# R7FA0E209 register map
Vendor: Renesas Electronics Corporation; Series: RA0; File version: 1.10.00
CPU: CM23 r1p0, little endian, no MPU, no FPU, VTOR, 2 interrupt priority bits, 64 interrupts
Registers are 16-bit, read-write, reset 0x0 unless marked. A register's access mark holds for its fields unless they carry their own. Offsets are from the block's base; [hi:lo] are bit positions; {n}, {i} and the like mark numbered series; 'fields as' and 'values as' point back to an identical list.

## SAU0 — Serial Array Unit 0
Base 0x400A2000
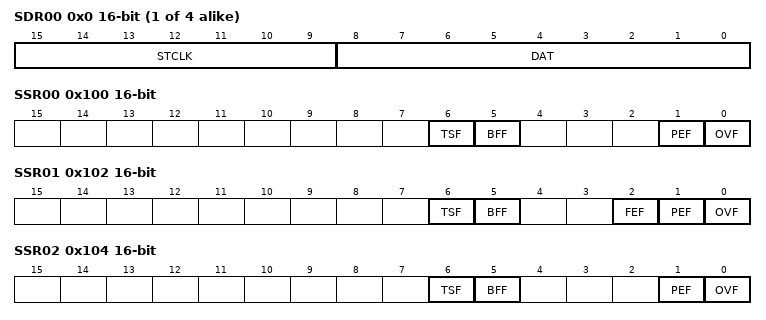
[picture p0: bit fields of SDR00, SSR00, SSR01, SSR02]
{0x0+2i} SDR0{i} (i=0..3) — Serial Data Register 0{i}
  [15:9] STCLK — Transfer Clock Setting by Dividing the Operation Clock
  [8:0] DAT — Data Buffer for Transmit and Receive
0x100 SSR00 ro — Serial Status Register 00
  [6] TSF — Flag Indicating the State of Communications for Channel n
    0=Communication is stopped or suspended; 1=Communication is in progress
  [5] BFF — Flag Indicating the State of the Buffer Register for Channel n
    0=Valid data is not stored in the SDRmn register; 1=Valid data is stored in the SDRmn register
  [1] PEF — Parity or ACK Error Detection Flag of Channel n
    0=No error occurs; 1=Parity error occurs (during UART reception), or ACK is not detected (during I2C transmission)
  [0] OVF — Overrun Error Detection Flag of Channel n
    0=No error occurs; 1=An error occurs
0x102 SSR01 ro — Serial Status Register 01
  [6] TSF — Flag Indicating the State of Communications for Channel n
    values as SSR00.TSF
  [5] BFF — Flag Indicating the State of the Buffer Register for Channel n
    values as SSR00.BFF
  [2] FEF — Framing Error Detection Flag of Channel n
    0=No error occurs; 1=An error occurs (during UART reception)
  [1] PEF — Parity or ACK Error Detection Flag of Channel n
    values as SSR00.PEF
  [0] OVF — Overrun Error Detection Flag of Channel n
    0=No error occurs; 1=An error occurs
0x104 SSR02 ro — Serial Status Register 02
  fields as SSR00
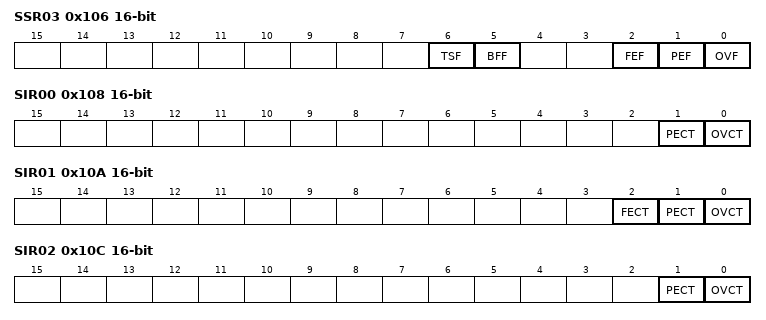
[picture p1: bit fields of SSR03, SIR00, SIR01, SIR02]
0x106 SSR03 ro — Serial Status Register 03
  fields as SSR01
0x108 SIR00 — Serial Flag Clear Trigger Register 00
  [1] PECT — Clear Trigger of Parity Error Flag of Channel n
    0=Not cleared; 1=Clears the PEF bit of the SSRmn register to 0
  [0] OVCT — Clear Trigger of Overrun Error Flag of Channel n
    0=Not cleared; 1=Clears the OVF bit of the SSRmn register to 0
0x10A SIR01 — Serial Flag Clear Trigger Register 01
  [2] FECT — Clear Trigger of Framing Error Flag of Channel n
    0=Not cleared; 1=Clears the FEF bit of the SSRmn register to 0
  [1] PECT — Clear Trigger of Parity Error Flag of Channel n
    values as SIR00.PECT
  [0] OVCT — Clear Trigger of Overrun Error Flag of Channel n
    values as SIR00.OVCT
0x10C SIR02 — Serial Flag Clear Trigger Register 02
  fields as SIR00
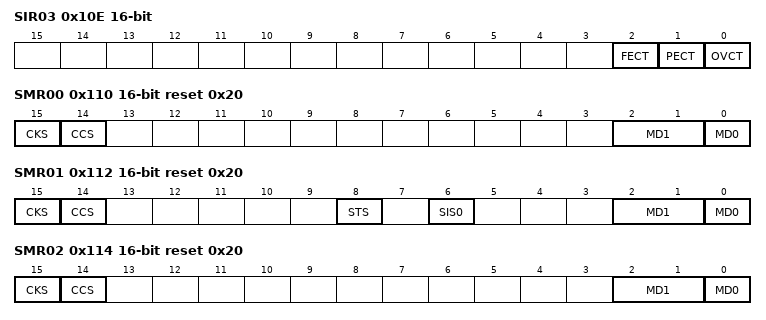
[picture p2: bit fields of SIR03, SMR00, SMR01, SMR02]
0x10E SIR03 — Serial Flag Clear Trigger Register 03
  fields as SIR01
0x110 SMR00 reset 0x20 — Serial Mode Register 00
  [15] CKS — Selection of Operation Clock (fMCK) of Channel n
    0=Operation clock CKm0 set by the SPSm register; 1=Operation clock CKm1 set by the SPSm register
  [14] CCS — Selection of Transfer Clock (fTCLK) of Channel n
    0=Divided operation clock fMCK specified by the CKS bit; 1=Clock input fSCK from the SCKp pin (slave transfer in simplified SPI mode)
  [2:1] MD1 — Setting of Channel n Operation Mode
    0=Simplified SPI mode; 1=UART mode; 2=Simplified I2C mode; 3=Setting prohibited
  [0] MD0 — Selection of Channel n Interrupt Source
    0=Transfer end interrupt; 1=Buffer empty interrupt (Occurs when data is transferred from the SDRmn register to the shift register.)
0x112 SMR01 reset 0x20 — Serial Mode Register 01
  [15] CKS — Selection of Operation Clock (fMCK) of Channel n
    values as SMR00.CKS
  [14] CCS — Selection of Transfer Clock (fTCLK) of Channel n
    values as SMR00.CCS
  [8] STS — Selection of Start Trigger Source
    0=Only software trigger is valid (selected for simplified SPI, UART transmission, and simplified I2C); 1=Valid edge of the RXDq pin (selected for UART reception)
  [6] SIS0 — Controls Inversion of Level of Channel n Receive Data in UART Mode
    0=Falling edge is detected as the start bit. The input communication data is captured as is.; 1=Rising edge is detected as the start bit. The input communication data is inverted and captured.
  [2:1] MD1 — Setting of Channel n Operation Mode
    values as SMR00.MD1
  [0] MD0 — Selection of Channel n Interrupt Source
    values as SMR00.MD0
0x114 SMR02 reset 0x20 — Serial Mode Register 02
  fields as SMR00
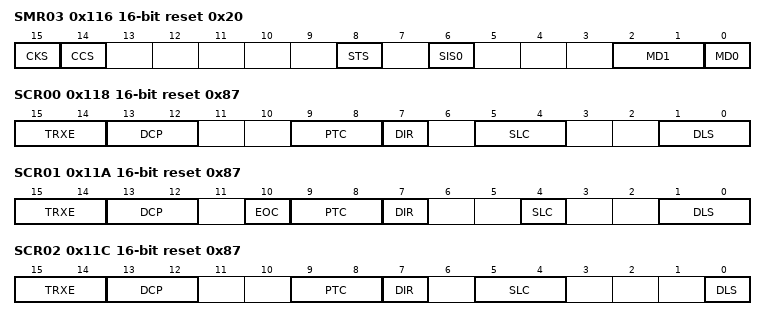
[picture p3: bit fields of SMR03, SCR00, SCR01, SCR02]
0x116 SMR03 reset 0x20 — Serial Mode Register 03
  fields as SMR01
0x118 SCR00 reset 0x87 — Serial Communication Operation Setting Register 00
  [15:14] TRXE — Setting of Channel 0 Operation Mode
    0=Disable communication; 1=Reception only; 2=Transmission only; 3=Transmission and reception
  [13:12] DCP — Selection of Data and Clock Phase in Simplified SPI Mode
    0=Type1 (SCK: inverted, Input timing: rising edge); 1=Type2 (SCK: non-inverted, Input timing: falling edge); 2=Type3 (SCK: inverted, Input timing: falling edge); 3=Type4 (SCK: non-inverted, Input timing: rising edge)
  [9:8] PTC — Setting of Parity Bit in UART Mode
    0=Transmission: Does not output the parity bit Reception: Receives without parity; 1=Transmission: Outputs 0 parity Reception: No parity determination; 2=Transmission: Outputs even parity Reception: Determines as even parity; 3=Transmission: Outputs odd parity Reception: Determines as odd parity
  [7] DIR — Selection of Data Transfer Sequence in Simplified SPI and UART Modes
    0=Inputs or outputs data with MSB first; 1=Inputs or outputs data with LSB first
  [5:4] SLC — Setting of Stop Bit in UART Mode
    0=No stop bit; 1=Stop bit length = 1 bit; 2=Stop bit length = 2 bits; 3=Setting prohibited
  [1:0] DLS — Setting of Data Length in Simplified SPI and UART Modes
    0=Setting prohibited; 1=9-bit data length (stored in bits 0 to 8 of the SDRm0 register) (settable in UART mode only); 2=7-bit data length (stored in bits 0 to 6 of the SDRm0 register); 3=8-bit data length (stored in bits 0 to 7 of the SDRm0 register)
0x11A SCR01 reset 0x87 — Serial Communication Operation Setting Register 01
  [15:14] TRXE — Setting of Channel 1 Operation Mode
    values as SCR00.TRXE
  [13:12] DCP — Selection of Data and Clock Phase in Simplified SPI Mode
    values as SCR00.DCP
  [10] EOC — Mask Control of Error Interrupt Signal SAU0_UART_ERRI0 (m = 0), SAU1_UART_ERRI2 (m = 1)
    0=Disables generation of error interrupt SAU0_UART_ERRI0 (m = 0), SAU1_UART_ERRI2 (m = 1) (SAUm_UART_RXIq is generated); 1=Enables generation of error interrupt SAU0_UART_ERRI0 (m = 0), SAU1_UART_ERRI2 (m = 1) (SAUm_UART_RXIq is not generated if an error occurs)
  [9:8] PTC — Setting of Parity Bit in UART Mode
    0=Transmission: Does not output the parity bit Reception: Receives without parity; 1=Transmission: Outputs 0 parity Reception: No parity judgment; 2=Transmission: Outputs even parity Reception: Determines as even parity; 3=Transmission: Outputs odd parity Reception: Determines as odd parity
  [7] DIR — Selection of Data Transfer Sequence in Simplified SPI and UART Modes
    values as SCR00.DIR
  [4] SLC — Setting of Stop Bit in UART Mode
    0=No stop bit; 1=Stop bit length = 1 bit
  [1:0] DLS — Setting of Data Length in Simplified SPI and UART Modes
    0=Setting prohibited; 1=9-bit data length (stored in the DAT[8:0] bits of the SDRm1 register) (settable in UART mode only); 2=7-bit data length (stored in the DAT[6:0] bits of the SDRm1 register); 3=8-bit data length (stored in the DAT[7:0] bits of the SDRm1 register)
0x11C SCR02 reset 0x87 — Serial Communication Operation Setting Register 02
  [15:14] TRXE — Setting of Channel 2 Operation Mode
    0=Disables communication; 1=Reception only; 2=Transmission only; 3=Transmission and reception
  [13:12] DCP — Selection of Data and Clock Phase in Simplified SPI Mode
    values as SCR00.DCP
  [9:8] PTC — Setting of Parity Bit in UART Mode
    values as SCR01.PTC
  [7] DIR — Selection of Data Transfer Sequence in Simplified SPI and UART Modes
    values as SCR00.DIR
  [5:4] SLC — Setting of Stop Bit in UART Mode
    values as SCR00.SLC
  [0] DLS — Setting of Data Length in Simplified SPI and UART Modes
    0=7-bit data length (stored in the DAT[6:0] bits of the SDR02 register); 1=8-bit data length (stored in the DAT[7:0] bits of the SDR02 register)
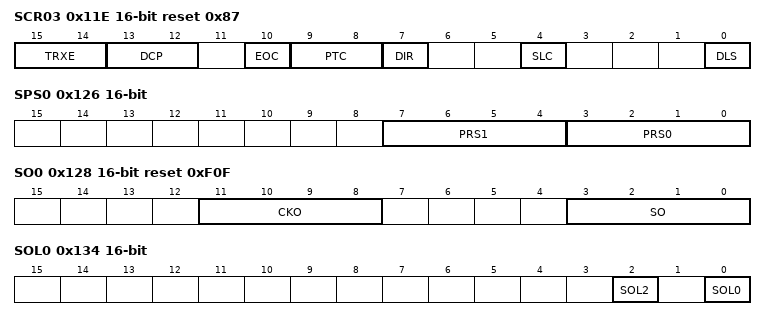
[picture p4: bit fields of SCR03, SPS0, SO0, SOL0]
0x11E SCR03 reset 0x87 — Serial Communication Operation Setting Register 03
  [15:14] TRXE — Setting of Operation Mode of Channel 3
    values as SCR00.TRXE
  [13:12] DCP — Selection of Data and Clock Phase in Simplified SPI Mode
    values as SCR00.DCP
  [10] EOC — Mask Control of Error Interrupt Signal SAU0_UART_ERRI1
    0=Disables generation of error interrupt SAU0_UART_ERRI1 (SAU0_UART_RXI1 is generated); 1=Enables generation of error interrupt SAU0_UART_ERRI1 (SAU0_UART_RXI1 is not generated if an error occurs)
  [9:8] PTC — Setting of Parity Bit in UART Mode
    values as SCR00.PTC
  [7] DIR — Selection of Data Transfer Sequence in Simplified SPI and UART Modes
    values as SCR00.DIR
  [4] SLC — Setting of Stop Bit in UART Mode
    0=No stop bit; 1=Stop bit length = 1 bit
  [0] DLS — Setting of Data Length in Simplified SPI and UART Modes
    0=7-bit data length (stored in the DAT[6:0] bits of the SDR03 register); 1=8-bit data length (stored in the DAT[7:0] bits of the SDR03 register)
0x120 SE0 ro — Serial Channel Enable Status Register 0
  [3:0] SE — Indication of whether Operation of Channel n is Enabled or Stopped.
    0=Operation stops; 1=Operation is enabled
0x122 SS0 — Serial Channel Start Register 0
  [3:0] SS — Operation Start Trigger of Channel n
    0=No trigger operation; 1=Set the SE0.SE[n] bit to 1 to place the channel in communications waiting state
0x124 ST0 — Serial Channel Stop Register 0
  [3:0] ST — Operation Stop Trigger of Channel n
    0=No trigger operation; 1=Clears the SE0.SE[n] bit to 0 and stops the communication operation
0x126 SPS0 — Serial Clock Select Register 0
  [7:4] PRS1 — Selection of Operation Clock (CKm1)
    0=PCLKB; 1=PCLKB/2; {v}=PCLKB/2^{v} (v=2..15)
  [3:0] PRS0 — Selection of Operation Clock (CKm0)
    0=PCLKB; 1=PCLKB/2; {v}=PCLKB/2^{v} (v=2..15)
0x128 SO0 reset 0xF0F — Serial Output Register 0
  [11:8] CKO — Serial Clock Output of Channel n
    0=Serial clock output value is 0; 1=Serial clock output value is 1
  [3:0] SO — Serial Data Output of Channel n
    0=Serial data output value is 0; 1=Serial data output value is 1
0x12A SOE0 — Serial Output Enable Register 0
  [3:0] SOE — Serial Output Enable or Stop of Channel n
    0=Stops output by serial communication operation; 1=Enables output by serial communication operation
0x134 SOL0 — Serial Output Level Register 0
  [2] SOL2 — Selects Inversion of the Level of the Transmit Data of Channel 2 in UART Mode
    0=Communication data is output as is; 1=Communication data is inverted and output
  [0] SOL0 — Selects Inversion of the Level of the Transmit Data of Channel 0 in UART Mode
    values as SOL2
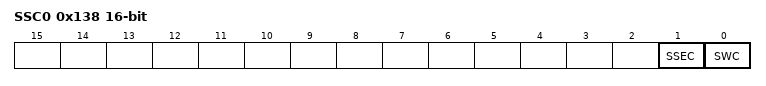
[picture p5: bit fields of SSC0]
0x138 SSC0 — Serial Standby Control Register 0
  [1] SSEC — Selection of whether to Enable or Disable the Generation of Communication Error Interrupts in the Snooze Mode
    0=Enable the generation of error interrupts SAU0_UART_ERRI0; 1=Disable the generation of error interrupts SAU0_UART_ERRI0
  [0] SWC — Setting of the Snooze Mode
    0=Do not use the Snooze mode function; 1=Use the Snooze mode function

## Notices in the file
This software is supplied by Renesas Electronics Corporation and is only intended for
use with Renesas products. No other uses are authorized. This software is owned by
Renesas Electronics Corporation and is protected under all applicable laws, including
copyright laws.
THIS SOFTWARE IS PROVIDED "AS IS" AND RENESAS MAKES NO WARRANTIES REGARDING
THIS SOFTWARE, WHETHER EXPRESS, IMPLIED OR STATUTORY, INCLUDING BUT NOT LIMITED TO
WARRANTIES OF MERCHANTABILITY, FITNESS FOR A PARTICULAR PURPOSE AND NON-INFRINGEMENT.
ALL SUCH WARRANTIES ARE EXPRESSLY DISCLAIMED. TO THE MAXIMUM EXTENT PERMITTED NOT
PROHIBITED BY LAW, NEITHER RENESAS ELECTRONICS CORPORATION NOR ANY OF ITS AFFILIATED
COMPANIES SHALL BE LIABLE FOR ANY DIRECT, INDIRECT, SPECIAL, INCIDENTAL OR CONSEQUENTIAL
DAMAGES FOR ANY REASON RELATED TO THIS SOFTWARE, EVEN IF RENESAS OR ITS AFFILIATES HAVE
BEEN ADVISED OF THE POSSIBILITY OF SUCH DAMAGES.
Renesas reserves the right, without notice, to make changes to this software and to
discontinue the availability of this software. By using this software, you agree to
the additional terms and conditions found by accessing the following link:
http://www.renesas.com/disclaimer
